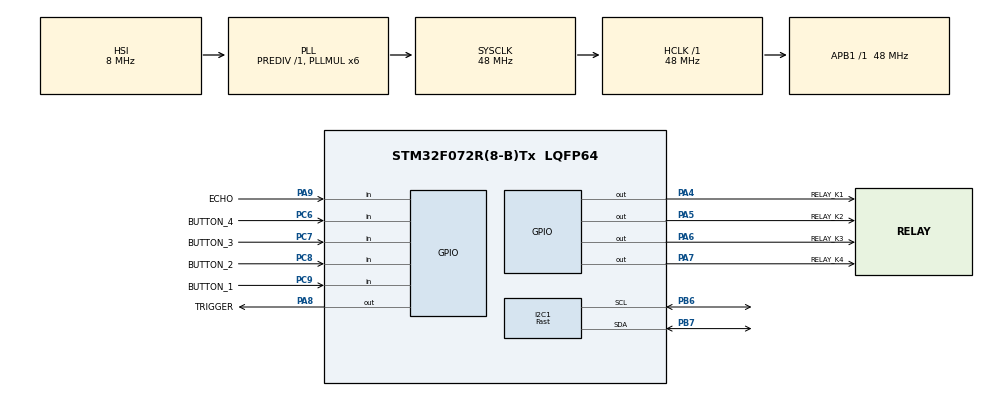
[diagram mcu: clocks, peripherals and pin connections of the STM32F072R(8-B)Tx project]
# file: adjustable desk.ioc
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I2C1.I2C_Speed_Mode=I2C_Fast
I2C1.Timing=0x0000020B
Mcu.Family=STM32F0
Mcu.Name=STM32F072R(8-B)Tx
Mcu.Package=LQFP64
PA13.Mode=Serial_Wire
PA13.Signal=SYS_SWDIO
PA14.Mode=Serial_Wire
PA14.Signal=SYS_SWCLK
PA4.GPIO_Label=RELAY_K1
PA4.Signal=GPIO_Output
PA5.GPIO_Label=RELAY_K2
PA5.Signal=GPIO_Output
PA6.GPIO_Label=RELAY_K3
PA6.Signal=GPIO_Output
PA7.GPIO_Label=RELAY_K4
PA7.Signal=GPIO_Output
PA8.GPIO_Label=TRIGGER
PA8.Signal=GPIO_Output
PA9.GPIO_Label=ECHO
PA9.Signal=GPIO_Input
PB6.Mode=I2C
PB6.Signal=I2C1_SCL
PB7.Mode=I2C
PB7.Signal=I2C1_SDA
PC6.GPIO_Label=BUTTON_4
PC6.Signal=GPIO_Input
PC7.GPIO_Label=BUTTON_3
PC7.Signal=GPIO_Input
PC8.GPIO_Label=BUTTON_2
PC8.Signal=GPIO_Input
PC9.GPIO_Label=BUTTON_1
PC9.Signal=GPIO_Input
PF0-OSC_IN.Mode=HSE-External-Oscillator
PF0-OSC_IN.Signal=RCC_OSC_IN
PF1-OSC_OUT.Mode=HSE-External-Oscillator
PF1-OSC_OUT.Signal=RCC_OSC_OUT
ProjectManager.HeapSize=0x200
ProjectManager.StackSize=0x400
ProjectManager.TargetToolchain=STM32CubeIDE
RCC.AHBFreq_Value=48000000
RCC.APB1Freq_Value=48000000
RCC.APB1TimFreq_Value=48000000
RCC.HCLKFreq_Value=48000000
RCC.PLLMUL=RCC_PLL_MUL6
RCC.SYSCLKFreq_VALUE=48000000
RCC.SYSCLKSource=RCC_SYSCLKSOURCE_PLLCLK
TIM15.Period=0
TIM15.Prescaler=48-1
VP_TIM15_VS_ClockSourceINT.Mode=Internal
board=STM32F072B-DISCO

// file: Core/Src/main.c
/* USER CODE BEGIN Header */
/**
  ******************************************************************************
  * @file           : main.c
  * @brief          : Main program body
  ******************************************************************************
  * @attention
  *
  * Copyright (c) 2022 STMicroelectronics.
  * All rights reserved.
  *
  * This software is licensed under terms that can be found in the LICENSE file
  * in the root directory of this software component.
  * If no LICENSE file comes with this software, it is provided AS-IS.
  *
  ******************************************************************************
  */
/* USER CODE END Header */
#include "main.h"

#include "ssd1306.h"
#include "fonts.h"
#include "test.h"

 I2C_HandleTypeDef hi2c1;

TIM_HandleTypeDef htim15;

void SystemClock_Config(void);
static void MX_GPIO_Init(void);
static void MX_I2C1_Init(void);
static void MX_TIM15_Init(void);

int main(void)
{

  /* MCU Configuration--------------------------------------------------------*/

  /* Reset of all peripherals, Initializes the Flash interface and the Systick. */
  HAL_Init();

  /* Configure the system clock */
  SystemClock_Config();

  /* Initialize all configured peripherals */
  MX_GPIO_Init();
  MX_I2C1_Init();
  MX_TIM15_Init();
  /* USER CODE BEGIN 2 */

  SSD1306_Init();

  /*SSD1306_GotoXY (10,10); // goto 10, 10
  SSD1306_Puts ("HELLO", &Font_11x18, 1);
  SSD1306_GotoXY (10, 30);
  SSD1306_Puts ("WORLD !!", &Font_11x18, 1);
  SSD1306_UpdateScreen();
  */

  uint32_t numTicks = 0;
  int distance = 0;

  char buffer [33];
  uint8_t x = 0;

  uint8_t button_1_state = 0;
  uint8_t button_2_state = 0;
  uint8_t button_3_state = 0;
  uint8_t button_4_state = 0;

  /* USER CODE END 2 */

  /* Infinite loop */
  /* USER CODE BEGIN WHILE */
  while (1){

	  HAL_GPIO_WritePin(TRIGGER_GPIO_Port, TRIGGER_Pin, GPIO_PIN_RESET);
	  		usDelay(3);

	  		//*** START Ultrasonic measure routine ***//
	  		//1. Output 10 usec TRIG
	  		HAL_GPIO_WritePin(TRIGGER_GPIO_Port, TRIGGER_Pin, GPIO_PIN_SET);
	  		usDelay(10);
	  		HAL_GPIO_WritePin(TRIGGER_GPIO_Port, TRIGGER_Pin, GPIO_PIN_RESET);

	  		//2. Wait for ECHO pin rising edge
	  		while(HAL_GPIO_ReadPin(ECHO_GPIO_Port, ECHO_Pin) == GPIO_PIN_RESET);

	  		numTicks = 0;
	  		while(HAL_GPIO_ReadPin(ECHO_GPIO_Port, ECHO_Pin) == GPIO_PIN_SET)
	  		{
	  			numTicks++;
	  			usDelay(2); // przez ograniczenia sprzetowe 2 mikro sekundy trwaja okolo 2.8 mikro sekundy
	  		};

	  		distance = (numTicks + 0.0f) * 2.8 * 0.0343 / 2;

	  //x++;
	  itoa (distance, buffer, 10); //funkcja zmienia int na string zeby pokazac na ekranie

	  SSD1306_GotoXY (10,10);
	  SSD1306_Puts ("Wysokosc:", &Font_11x18, 1);
	  SSD1306_GotoXY (10, 30);
	  SSD1306_Puts (buffer, &Font_11x18, 1);
	  SSD1306_GotoXY (70, 30);
	  SSD1306_Puts ("cm", &Font_11x18, 1);
	  SSD1306_UpdateScreen();
	  //HAL_Delay(2000);

	  button_1_state = HAL_GPIO_ReadPin(BUTTON_1_GPIO_Port, BUTTON_1_Pin);
	  button_2_state = HAL_GPIO_ReadPin(BUTTON_2_GPIO_Port, BUTTON_2_Pin);
	  button_3_state = HAL_GPIO_ReadPin(BUTTON_3_GPIO_Port, BUTTON_3_Pin);
	  button_4_state = HAL_GPIO_ReadPin(BUTTON_4_GPIO_Port, BUTTON_4_Pin);

	  if((button_1_state == 0) && (distance > 20)){

		  HAL_GPIO_WritePin(RELAY_K1_GPIO_Port, RELAY_K1_Pin, SET);
		  HAL_GPIO_WritePin(RELAY_K2_GPIO_Port, RELAY_K2_Pin, SET);

	  }else{

		  HAL_GPIO_WritePin(RELAY_K1_GPIO_Port, RELAY_K1_Pin, RESET);
		  HAL_GPIO_WritePin(RELAY_K2_GPIO_Port, RELAY_K2_Pin, RESET);

	  }

/*	  if(button_2_state == 1){

	  	  HAL_GPIO_WritePin(RELAY_K2_GPIO_Port, RELAY_K2_Pin, SET);

	  }else{

	  	  HAL_GPIO_WritePin(RELAY_K2_GPIO_Port, RELAY_K2_Pin, RESET);

*/	  }

	  if((button_2_state == 0) && (distance < 120)){

	  	  HAL_GPIO_WritePin(RELAY_K3_GPIO_Port, RELAY_K3_Pin, SET);
	  	  HAL_GPIO_WritePin(RELAY_K4_GPIO_Port, RELAY_K4_Pin, SET);

	  }else{

	  	  HAL_GPIO_WritePin(RELAY_K3_GPIO_Port, RELAY_K3_Pin, RESET);
	  	HAL_GPIO_WritePin(RELAY_K4_GPIO_Port, RELAY_K4_Pin, RESET);

	  }

	  /*	  if(button_4_state == 0){

	  	  HAL_GPIO_WritePin(RELAY_K4_GPIO_Port, RELAY_K4_Pin, SET);

	  }else{

	  	  HAL_GPIO_WritePin(RELAY_K4_GPIO_Port, RELAY_K4_Pin, RESET);

	  		  }
*/
    // USER CODE BEGIN 3 */
  //}
  /* USER CODE END 3 */
}

void usDelay(uint32_t uSec)
{
	if(uSec < 2) uSec = 2;
	TIM15->ARR = uSec - 1; 	/*sets the value in the auto-reload register*/
	TIM15->EGR = 1; 			/*Re-initialises the timer*/
	TIM15->SR &= ~1; 		//Resets the flag
	TIM15->CR1 |= 1; 		//Enables the counter
	while((TIM15->SR&0x0001) != 1);
	TIM15->SR &= ~(0x0001);
}

void SystemClock_Config(void)
{
  RCC_OscInitTypeDef RCC_OscInitStruct = {0};
  RCC_ClkInitTypeDef RCC_ClkInitStruct = {0};
  RCC_PeriphCLKInitTypeDef PeriphClkInit = {0};

  /** Initializes the RCC Oscillators according to the specified parameters
  * in the RCC_OscInitTypeDef structure.
  */
  RCC_OscInitStruct.OscillatorType = RCC_OSCILLATORTYPE_HSI;
  RCC_OscInitStruct.HSIState = RCC_HSI_ON;
  RCC_OscInitStruct.HSICalibrationValue = RCC_HSICALIBRATION_DEFAULT;
  RCC_OscInitStruct.PLL.PLLState = RCC_PLL_ON;
  RCC_OscInitStruct.PLL.PLLSource = RCC_PLLSOURCE_HSI;
  RCC_OscInitStruct.PLL.PLLMUL = RCC_PLL_MUL6;
  RCC_OscInitStruct.PLL.PREDIV = RCC_PREDIV_DIV1;
  if (HAL_RCC_OscConfig(&RCC_OscInitStruct) != HAL_OK)
  {
    Error_Handler();
  }

  /** Initializes the CPU, AHB and APB buses clocks
  */
  RCC_ClkInitStruct.ClockType = RCC_CLOCKTYPE_HCLK|RCC_CLOCKTYPE_SYSCLK
                              |RCC_CLOCKTYPE_PCLK1;
  RCC_ClkInitStruct.SYSCLKSource = RCC_SYSCLKSOURCE_PLLCLK;
  RCC_ClkInitStruct.AHBCLKDivider = RCC_SYSCLK_DIV1;
  RCC_ClkInitStruct.APB1CLKDivider = RCC_HCLK_DIV1;

  if (HAL_RCC_ClockConfig(&RCC_ClkInitStruct, FLASH_LATENCY_1) != HAL_OK)
  {
    Error_Handler();
  }
  PeriphClkInit.PeriphClockSelection = RCC_PERIPHCLK_I2C1;
  PeriphClkInit.I2c1ClockSelection = RCC_I2C1CLKSOURCE_HSI;
  if (HAL_RCCEx_PeriphCLKConfig(&PeriphClkInit) != HAL_OK)
  {
    Error_Handler();
  }
}

static void MX_I2C1_Init(void)
{

  hi2c1.Instance = I2C1;
  hi2c1.Init.Timing = 0x0000020B;
  hi2c1.Init.OwnAddress1 = 0;
  hi2c1.Init.AddressingMode = I2C_ADDRESSINGMODE_7BIT;
  hi2c1.Init.DualAddressMode = I2C_DUALADDRESS_DISABLE;
  hi2c1.Init.OwnAddress2 = 0;
  hi2c1.Init.OwnAddress2Masks = I2C_OA2_NOMASK;
  hi2c1.Init.GeneralCallMode = I2C_GENERALCALL_DISABLE;
  hi2c1.Init.NoStretchMode = I2C_NOSTRETCH_DISABLE;
  if (HAL_I2C_Init(&hi2c1) != HAL_OK)
  {
    Error_Handler();
  }

  /** Configure Analogue filter
  */
  if (HAL_I2CEx_ConfigAnalogFilter(&hi2c1, I2C_ANALOGFILTER_ENABLE) != HAL_OK)
  {
    Error_Handler();
  }

  /** Configure Digital filter
  */
  if (HAL_I2CEx_ConfigDigitalFilter(&hi2c1, 0) != HAL_OK)
  {
    Error_Handler();
  }

}

static void MX_TIM15_Init(void)
{

  TIM_ClockConfigTypeDef sClockSourceConfig = {0};
  TIM_MasterConfigTypeDef sMasterConfig = {0};

  htim15.Instance = TIM15;
  htim15.Init.Prescaler = 48-1;
  htim15.Init.CounterMode = TIM_COUNTERMODE_UP;
  htim15.Init.Period = 0;
  htim15.Init.ClockDivision = TIM_CLOCKDIVISION_DIV1;
  htim15.Init.RepetitionCounter = 0;
  htim15.Init.AutoReloadPreload = TIM_AUTORELOAD_PRELOAD_DISABLE;
  if (HAL_TIM_Base_Init(&htim15) != HAL_OK)
  {
    Error_Handler();
  }
  sClockSourceConfig.ClockSource = TIM_CLOCKSOURCE_INTERNAL;
  if (HAL_TIM_ConfigClockSource(&htim15, &sClockSourceConfig) != HAL_OK)
  {
    Error_Handler();
  }
  sMasterConfig.MasterOutputTrigger = TIM_TRGO_RESET;
  sMasterConfig.MasterSlaveMode = TIM_MASTERSLAVEMODE_DISABLE;
  if (HAL_TIMEx_MasterConfigSynchronization(&htim15, &sMasterConfig) != HAL_OK)
  {
    Error_Handler();
  }

}

static void MX_GPIO_Init(void)
{
  GPIO_InitTypeDef GPIO_InitStruct = {0};

  /* GPIO Ports Clock Enable */
  __HAL_RCC_GPIOF_CLK_ENABLE();
  __HAL_RCC_GPIOA_CLK_ENABLE();
  __HAL_RCC_GPIOC_CLK_ENABLE();
  __HAL_RCC_GPIOB_CLK_ENABLE();

  /*Configure GPIO pin Output Level */
  HAL_GPIO_WritePin(GPIOA, RELAY_K1_Pin|RELAY_K2_Pin|RELAY_K3_Pin|RELAY_K4_Pin
                          |TRIGGER_Pin, GPIO_PIN_RESET);

  /*Configure GPIO pins : RELAY_K1_Pin RELAY_K2_Pin RELAY_K3_Pin RELAY_K4_Pin
                           TRIGGER_Pin */
  GPIO_InitStruct.Pin = RELAY_K1_Pin|RELAY_K2_Pin|RELAY_K3_Pin|RELAY_K4_Pin
                          |TRIGGER_Pin;
  GPIO_InitStruct.Mode = GPIO_MODE_OUTPUT_PP;
  GPIO_InitStruct.Pull = GPIO_NOPULL;
  GPIO_InitStruct.Speed = GPIO_SPEED_FREQ_LOW;
  HAL_GPIO_Init(GPIOA, &GPIO_InitStruct);

  /*Configure GPIO pins : BUTTON_4_Pin BUTTON_3_Pin BUTTON_2_Pin BUTTON_1_Pin */
  GPIO_InitStruct.Pin = BUTTON_4_Pin|BUTTON_3_Pin|BUTTON_2_Pin|BUTTON_1_Pin;
  GPIO_InitStruct.Mode = GPIO_MODE_INPUT;
  GPIO_InitStruct.Pull = GPIO_NOPULL;
  HAL_GPIO_Init(GPIOC, &GPIO_InitStruct);

  /*Configure GPIO pin : ECHO_Pin */
  GPIO_InitStruct.Pin = ECHO_Pin;
  GPIO_InitStruct.Mode = GPIO_MODE_INPUT;
  GPIO_InitStruct.Pull = GPIO_NOPULL;
  HAL_GPIO_Init(ECHO_GPIO_Port, &GPIO_InitStruct);

}

void Error_Handler(void)
{
  __disable_irq();
  while (1)
  {
  }
}
